VERSION "Excel 2 DBC"

NS_ :

BS_:

BU_: FCMS

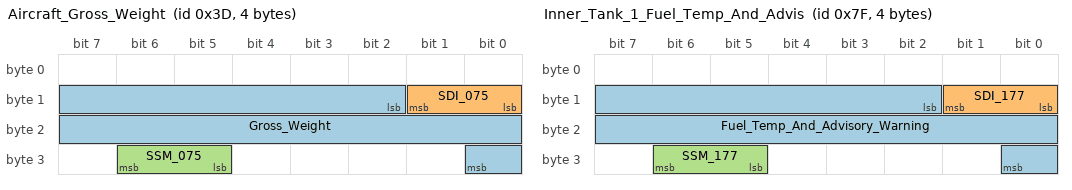
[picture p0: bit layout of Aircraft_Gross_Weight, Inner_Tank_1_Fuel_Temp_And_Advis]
BO_ 61 Aircraft_Gross_Weight: 4 FCMS
 SG_ Gross_Weight : 10|15@1+ (40,0) [0|1310720] "lbs" Vector__XXX
 SG_ SDI_075 : 8|2@1+ (1,0) [0|3] "" Vector__XXX
 SG_ SSM_075 : 29|2@1+ (1,0) [0|3] "" Vector__XXX

BO_ 96 Fuel_Pump_Contactor: 4 FCMS
 SG_ Main_Pump_1 : 11|1@1+ (1,0) [0|1] "" Vector__XXX
 SG_ Standby_Pump_1 : 10|1@1+ (1,0) [0|1] "" Vector__XXX
 SG_ Standby_Pump_2 : 12|1@1+ (1,0) [0|1] "" Vector__XXX
 SG_ Main_Pump_2 : 13|1@1+ (1,0) [0|1] "" Vector__XXX
 SG_ SDI_140 : 8|2@1+ (1,0) [0|3] "" Vector__XXX
 SG_ SSM_140 : 29|2@1+ (1,0) [0|3] "" Vector__XXX
 SG_ Main_Pump_3 : 15|1@1+ (1,0) [0|1] "" Vector__XXX
 SG_ Main_Pump_4 : 17|1@1+ (1,0) [0|1] "" Vector__XXX
 SG_ Standby_Pump_3 : 14|1@1+ (1,0) [0|1] "" Vector__XXX
 SG_ Standby_Pump_4 : 16|1@1+ (1,0) [0|1] "" Vector__XXX
 SG_ Center_Tank_Left_Transfer_Pump : 18|1@1+ (1,0) [0|1] "" Vector__XXX
 SG_ Center_Tank_Right_Transfer_Pump : 19|1@1+ (1,0) [0|1] "" Vector__XXX
 SG_ Center_Tank_Left_Aft_Transfer_Pu : 20|1@1+ (1,0) [0|1] "" Vector__XXX
 SG_ Center_Tank_Right_Aft_Transfer_P : 21|1@1+ (1,0) [0|1] "" Vector__XXX
 SG_ Act_Transfer_Pump : 22|1@1+ (1,0) [0|1] "" Vector__XXX
 SG_ Trim_Tank_Left_Transfer_Pump : 23|1@1+ (1,0) [0|1] "" Vector__XXX
 SG_ Trim_Tank_Right_Transfer_Pump : 24|1@1+ (1,0) [0|1] "" Vector__XXX
 SG_ Inner_1_Tank_Aft_Transfer_Pump : 25|1@1+ (1,0) [0|1] "" Vector__XXX
 SG_ Inner_2_Tank_Aft_Transfer_Pump : 26|1@1+ (1,0) [0|1] "" Vector__XXX
 SG_ Inner_3_Tank_Aft_Transfer_Pump : 27|1@1+ (1,0) [0|1] "" Vector__XXX
 SG_ Inner_4_Tank_Aft_Transfer_Pump : 28|1@1+ (1,0) [0|1] "" Vector__XXX

BO_ 127 Inner_Tank_1_Fuel_Temp_And_Advis: 4 Vector__XXX
 SG_ Fuel_Temp_And_Advisory_Warning : 10|15@1- (0.25,0) [-512|512] "" FCMS
 SG_ SDI_177 : 8|2@1+ (1,0) [0|3] "" FCMS
 SG_ SSM_177 : 29|2@1+ (1,0) [0|3] "" FCMS

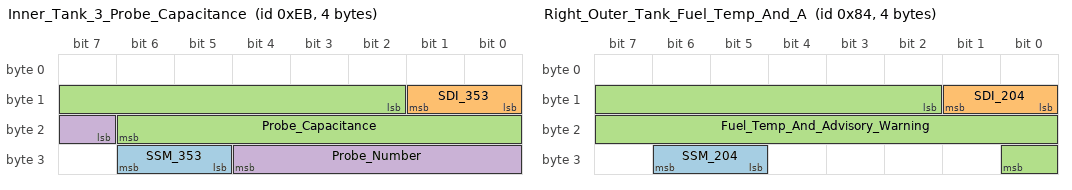
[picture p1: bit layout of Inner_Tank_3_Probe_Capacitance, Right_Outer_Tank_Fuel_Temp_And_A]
BO_ 235 Inner_Tank_3_Probe_Capacitance: 4 Vector__XXX
 SG_ SSM_353 : 29|2@1+ (1,0) [0|3] "" FCMS
 SG_ SDI_353 : 8|2@1+ (1,0) [0|3] "" FCMS
 SG_ Probe_Capacitance : 10|13@1- (1,0) [0|400] "" FCMS
 SG_ Probe_Number : 23|6@1- (1,0) [0|30] "" FCMS

BO_ 107 Level_States: 4 FCMS
 SG_ Act1_High_Level : 24|1@1+ (1,0) [0|1] "" Vector__XXX
 SG_ Act1_Low_Level : 25|1@1+ (1,0) [0|1] "" Vector__XXX
 SG_ Act2_High_Level : 26|1@1+ (1,0) [0|1] "" Vector__XXX
 SG_ Act2_Low_Level : 27|1@1+ (1,0) [0|1] "" Vector__XXX
 SG_ Center_Tank_High_Level : 17|1@1+ (1,0) [0|1] "" Vector__XXX
 SG_ Center_Tank_Low_Level : 16|1@1+ (1,0) [0|1] "" Vector__XXX
 SG_ Inner_Tank_1_High_Level : 12|1@1+ (1,0) [0|1] "" Vector__XXX
 SG_ Inner_Tank_1_Low_Level : 13|1@1+ (1,0) [0|1] "" Vector__XXX
 SG_ Inner_Tank_2_High_Level : 14|1@1+ (1,0) [0|1] "" Vector__XXX
 SG_ Inner_Tank_2_Low_Level : 15|1@1+ (1,0) [0|1] "" Vector__XXX
 SG_ Inner_Tank_3_High_Level : 18|1@1+ (1,0) [0|1] "" Vector__XXX
 SG_ Inner_Tank_3_Low_Level : 20|1@1+ (1,0) [0|1] "" Vector__XXX
 SG_ Inner_Tank_4_High_Level : 19|1@1+ (1,0) [0|1] "" Vector__XXX
 SG_ Inner_Tank_4_Low_Level : 21|1@1+ (1,0) [0|1] "" Vector__XXX
 SG_ Left_Outer_High_Level : 11|1@1+ (1,0) [0|1] "" Vector__XXX
 SG_ Left_Surge_Tank : 10|1@1+ (1,0) [0|1] "" Vector__XXX
 SG_ PAD : 28|1@1+ (1,0) [0|1] "" Vector__XXX
 SG_ Right_Outer_High_Level : 22|1@1+ (1,0) [0|1] "" Vector__XXX
 SG_ Right_Surge_Tank : 23|1@1+ (1,0) [0|1] "" Vector__XXX
 SG_ SDI_153 : 8|2@1+ (1,0) [0|3] "" Vector__XXX
 SG_ SSM_153 : 29|2@1+ (1,0) [0|3] "" Vector__XXX

BO_ 97 Pump_Contactor_And_Pushbutton_St: 4 FCMS
 SG_ Center_Tank_Right_Transfer_Pump_ : 22|1@1+ (1,0) [0|1] "" FCMS
 SG_ Center_Tank_Left_Aft_Transf_0000 : 23|1@1+ (1,0) [0|1] "" FCMS
 SG_ Center_Tank_Right_Aft_Trans_0000 : 24|1@1+ (1,0) [0|1] "" FCMS
 SG_ Trim_Tank_Left_Transfer_Pump_Pus : 25|1@1+ (1,0) [0|1] "" FCMS
 SG_ Trim_Tank_Right_Transfer_Pump_Pu : 26|1@1+ (1,0) [0|1] "" FCMS
 SG_ RCT_Transfer_Pump_A_Front_Pushbu : 27|1@1+ (1,0) [0|1] "" FCMS
 SG_ RCT_Transfer_Pump_B_Rear_Pushbut : 28|1@1+ (1,0) [0|1] "" FCMS
 SG_ Main_Pump_1_Pushbutton : 13|1@1+ (1,0) [0|1] "" FCMS
 SG_ Main_Pump_2_Pushbutton : 15|1@1+ (1,0) [0|1] "" FCMS
 SG_ Main_Pump_3_Pushbutton : 17|1@1+ (1,0) [0|1] "" FCMS
 SG_ Main_Pump_4_Pushbutton : 19|1@1+ (1,0) [0|1] "" FCMS
 SG_ RCT_Transfer_Pump_A_Front_Contac : 10|1@1+ (1,0) [0|1] "" FCMS
 SG_ RCT_Transfer_Pump_B_Rear_Contact : 11|1@1+ (1,0) [0|1] "" FCMS
 SG_ Center_Tank_Left_Transfer_Pump_P : 21|1@1+ (1,0) [0|1] "" FCMS
 SG_ APU_Pump_Contactor : 12|1@1+ (1,0) [0|1] "" FCMS
 SG_ Standby_Pump_2_Pushbutton : 16|1@1+ (1,0) [0|1] "" FCMS
 SG_ Standby_Pump_3_Pushbutton : 18|1@1+ (1,0) [0|1] "" FCMS
 SG_ Standby_Pump_4_Pushbutton : 20|1@1+ (1,0) [0|1] "" FCMS
 SG_ Standby_Pump_1_Pushbutton : 14|1@1+ (1,0) [0|1] "" FCMS
 SG_ SDI_141 : 8|2@1+ (1,0) [0|3] "" FCMS
 SG_ SSM_141 : 29|2@1+ (1,0) [0|3] "" FCMS

BO_ 132 Right_Outer_Tank_Fuel_Temp_And_A: 4 Vector__XXX
 SG_ SSM_204 : 29|2@1+ (1,0) [0|3] "" FCMS
 SG_ SDI_204 : 8|2@1+ (1,0) [0|3] "" FCMS
 SG_ Fuel_Temp_And_Advisory_Warning : 10|15@1- (0.25,0) [-512|512] "" FCMS

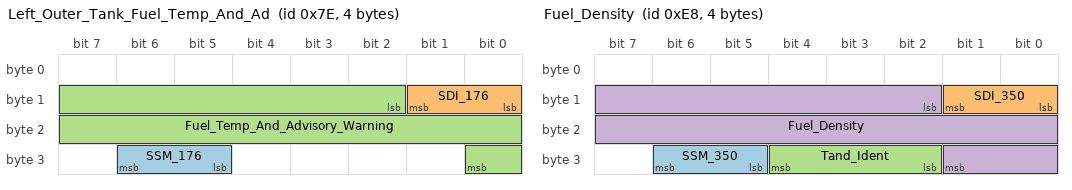
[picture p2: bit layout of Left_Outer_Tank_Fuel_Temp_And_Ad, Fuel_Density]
BO_ 126 Left_Outer_Tank_Fuel_Temp_And_Ad: 4 Vector__XXX
 SG_ SSM_176 : 29|2@1+ (1,0) [0|3] "" FCMS
 SG_ SDI_176 : 8|2@1+ (1,0) [0|3] "" FCMS
 SG_ Fuel_Temp_And_Advisory_Warning : 10|15@1- (0.25,0) [-512|512] "" FCMS

BO_ 232 Fuel_Density: 4 Vector__XXX
 SG_ SSM_350 : 29|2@1+ (1,0) [0|3] "" FCMS
 SG_ SDI_350 : 8|2@1+ (1,0) [0|3] "" FCMS
 SG_ Tand_Ident : 26|3@1+ (1,0) [0|7] "" FCMS
 SG_ Fuel_Density : 10|16@1- (1,0) [0|1] "kg/l" FCMS

VAL_ 61 SSM_075 0 "Normal Operation " 1 "NCD" 2 "Functional Test" 3 "Failure Warning ";
VAL_ 96 Main_Pump_1 0 "Energized" 1 "Off";
VAL_ 96 Standby_Pump_1 0 "Energized" 1 "Off";
VAL_ 96 Standby_Pump_2 0 "Energized" 1 "Off";
VAL_ 96 Main_Pump_2 0 "Energized" 1 "Off";
VAL_ 96 SDI_140 1 "Computer 1" 2 "Computer 2";
VAL_ 96 SSM_140 0 "Normal Operation " 1 "NCD" 2 "Functional Test" 3 "Failure Warning ";
VAL_ 96 Main_Pump_3 0 "Energized" 1 "Off";
VAL_ 96 Main_Pump_4 0 "Energized" 1 "Off";
VAL_ 96 Standby_Pump_3 0 "Energized" 1 "Off";
VAL_ 96 Standby_Pump_4 0 "Energized" 1 "Off";
VAL_ 96 Center_Tank_Left_Transfer_Pump 0 "Energized" 1 "Off";
VAL_ 96 Center_Tank_Right_Transfer_Pump 0 "Energized" 1 "Off";
VAL_ 96 Center_Tank_Left_Aft_Transfer_Pu 0 "Energized" 1 "Off";
VAL_ 96 Center_Tank_Right_Aft_Transfer_P 0 "Energized" 1 "Off";
VAL_ 96 Act_Transfer_Pump 0 "Energized" 1 "Off";
VAL_ 96 Trim_Tank_Left_Transfer_Pump 0 "Energized" 1 "Off";
VAL_ 96 Trim_Tank_Right_Transfer_Pump 0 "Energized" 1 "Off";
VAL_ 96 Inner_1_Tank_Aft_Transfer_Pump 0 "Energized" 1 "Off";
VAL_ 96 Inner_2_Tank_Aft_Transfer_Pump 0 "Energized" 1 "Off";
VAL_ 96 Inner_3_Tank_Aft_Transfer_Pump 0 "Energized" 1 "Off";
VAL_ 96 Inner_4_Tank_Aft_Transfer_Pump 0 "Energized" 1 "Off";
VAL_ 127 SSM_177 0 "Normal Operation " 1 "NCD" 2 "Functional Test" 3 "Failure Warning ";
VAL_ 235 SSM_353 0 "Normal Operation " 1 "NCD" 2 "Functional Test" 3 "Failure Warning ";
VAL_ 107 Act1_High_Level 0 "Not High" 1 "High";
VAL_ 107 Act1_Low_Level 0 "Not Low" 1 "Low";
VAL_ 107 Act2_High_Level 0 "Not High" 1 "High";
VAL_ 107 Act2_Low_Level 0 "Not Low" 1 "Low";
VAL_ 107 Center_Tank_High_Level 0 "Not High" 1 "High";
VAL_ 107 Center_Tank_Low_Level 0 "Not Low" 1 "Low";
VAL_ 107 Inner_Tank_1_High_Level 0 "Not High" 1 "High";
VAL_ 107 Inner_Tank_1_Low_Level 0 "Not Low" 1 "Low";
VAL_ 107 Inner_Tank_2_High_Level 0 "Not High" 1 "High";
VAL_ 107 Inner_Tank_2_Low_Level 0 "Not Low" 1 "Low";
VAL_ 107 Inner_Tank_3_High_Level 0 "Not High" 1 "High";
VAL_ 107 Inner_Tank_3_Low_Level 0 "Not Low" 1 "Low";
VAL_ 107 Inner_Tank_4_High_Level 0 "Not High" 1 "High";
VAL_ 107 Inner_Tank_4_Low_Level 0 "Not Low" 1 "Low";
VAL_ 107 Left_Outer_High_Level 0 "Not High" 1 "High";
VAL_ 107 Left_Surge_Tank 0 "Not Wet" 1 "Wet";
VAL_ 107 Right_Outer_High_Level 0 "Not High" 1 "High";
VAL_ 107 Right_Surge_Tank 0 "Not Wet" 1 "Wet";
VAL_ 107 SDI_153 1 "Computer 1" 2 "Computer 2";
VAL_ 107 SSM_153 0 "Normal Operation " 1 "NCD" 2 "Functional Test" 3 "Failure Warning ";
VAL_ 97 Center_Tank_Right_Transfer_Pump_ 0 "Off" 1 "On";
VAL_ 97 Center_Tank_Left_Aft_Transf_0000 0 "Off" 1 "On";
VAL_ 97 Center_Tank_Right_Aft_Trans_0000 0 "Off" 1 "On";
VAL_ 97 Trim_Tank_Left_Transfer_Pump_Pus 0 "Off" 1 "On";
VAL_ 97 Trim_Tank_Right_Transfer_Pump_Pu 0 "Off" 1 "On";
VAL_ 97 RCT_Transfer_Pump_A_Front_Pushbu 0 "Off" 1 "On";
VAL_ 97 RCT_Transfer_Pump_B_Rear_Pushbut 0 "Off" 1 "On";
VAL_ 97 Main_Pump_1_Pushbutton 0 "Off" 1 "On";
VAL_ 97 Main_Pump_2_Pushbutton 0 "Off" 1 "On";
VAL_ 97 Main_Pump_3_Pushbutton 0 "Off" 1 "On";
VAL_ 97 Main_Pump_4_Pushbutton 0 "Off" 1 "On";
VAL_ 97 RCT_Transfer_Pump_A_Front_Contac 0 "Energized" 1 "Off";
VAL_ 97 RCT_Transfer_Pump_B_Rear_Contact 0 "Energized" 1 "Off";
VAL_ 97 Center_Tank_Left_Transfer_Pump_P 0 "Off" 1 "On";
VAL_ 97 APU_Pump_Contactor 0 "Energized" 1 "Off";
VAL_ 97 Standby_Pump_2_Pushbutton 0 "Off" 1 "On";
VAL_ 97 Standby_Pump_3_Pushbutton 0 "Off" 1 "On";
VAL_ 97 Standby_Pump_4_Pushbutton 0 "Off" 1 "On";
VAL_ 97 Standby_Pump_1_Pushbutton 0 "Off" 1 "On";
VAL_ 97 SDI_141 1 "Computer 1" 2 "Computer 2";
VAL_ 97 SSM_141 0 "Normal Operation " 1 "NCD" 2 "Functional Test" 3 "Failure Warning ";
VAL_ 132 SSM_204 0 "Normal Operation " 1 "NCD" 2 "Functional Test" 3 "Failure Warning ";
VAL_ 126 SSM_176 0 "Normal Operation " 1 "NCD" 2 "Functional Test" 3 "Failure Warning ";
VAL_ 232 SSM_350 0 "Normal Operation " 1 "NCD" 2 "Functional Test" 3 "Failure Warning ";
